# SAM9X60 device description
Architecture: ARM926EJS; Family: SAM9; Series: SAM9X
Registers are 32-bit, read-write, no defined reset value unless marked. A register's access mark holds for its fields unless they carry their own. Offsets are from the block's base; [hi:lo] are bit positions; {n}, {i} and the like mark numbered series.

## CLASSD — Audio Class D Amplifier (CLASSD)
Instances: CLASSD 0xF003C000
0x00 CLASSD_CR wo — Control Register
  [0] SWRST — Software Reset
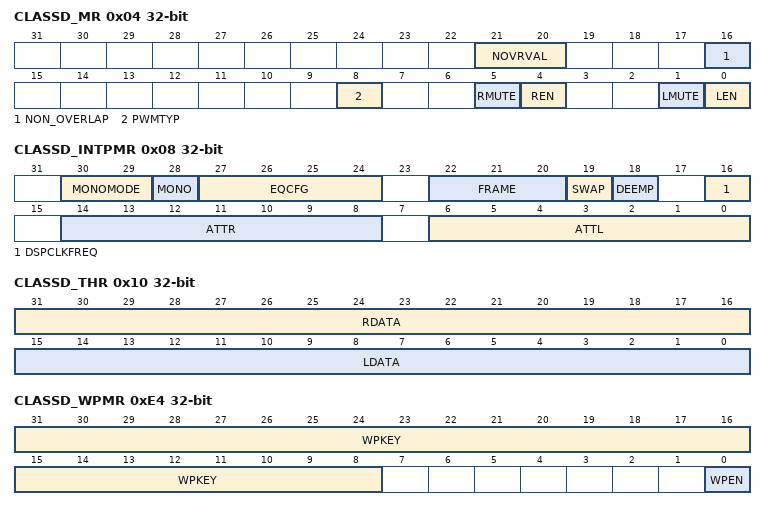
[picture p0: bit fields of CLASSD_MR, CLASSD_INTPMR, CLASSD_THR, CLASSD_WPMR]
0x04 CLASSD_MR — Mode Register
  [21:20] NOVRVAL — Non-Overlapping Value
    0=_5NS (Non-overlapping time is 5 ns); 1=_10NS (Non-overlapping time is 10 ns); 2=_15NS (Non-overlapping time is 15 ns); 3=_20NS (Non-overlapping time is 20 ns)
  [16] NON_OVERLAP — Non-Overlapping Enable
  [8] PWMTYP — PWM Modulation Type
  [5] RMUTE — Right Channel Mute
  [4] REN — Right Channel Enable
  [1] LMUTE — Left Channel Mute
  [0] LEN — Left Channel Enable
0x08 CLASSD_INTPMR — Interpolator Mode Register
  [30:29] MONOMODE — Mono Mode Selection
    0=MONOMIX ((left + right) / 2 is sent on both channels); 1=MONOSAT ((left + right) is sent to both channels. If the sum is too high, the result is saturated.); 2=MONOLEFT (THR[15:0] is sent on both left and right channels); 3=MONORIGHT (THR[31:16] is sent on both left and right channels)
  [28] MONO — Mono Signal
    0=DISABLED (The signal is sent stereo to the left and right channels.); 1=ENABLED (The same signal is sent on both left and right channels. The sent signal is defined by the MONOMODE field value.)
  [27:24] EQCFG — Equalization Selection
    0=FLAT (Flat Response); 1=BBOOST12 (Bass boost +12 dB); 2=BBOOST6 (Bass boost +6 dB); 3=BCUT12 (Bass cut -12 dB); 4=BCUT6 (Bass cut -6 dB); 5=MBOOST3 (Medium boost +3 dB); 6=MBOOST8 (Medium boost +8 dB); 7=MCUT3 (Medium cut -3 dB); 8=MCUT8 (Medium cut -8 dB); 9=TBOOST12 (Treble boost +12 dB); 10=TBOOST6 (Treble boost +6 dB); 11=TCUT12 (Treble cut -12 dB); 12=TCUT6 (Treble cut -6 dB)
  [22:20] FRAME — CLASSD Incoming Data Sampling Frequency
    0=FRAME_8K (8 kHz); 1=FRAME_16K (16 kHz); 2=FRAME_32K (32 kHz); 3=FRAME_48K (48 kHz); 4=FRAME_96K (96 kHz); 5=FRAME_22K (22.05 kHz); 6=FRAME_44K (44.1 kHz); 7=FRAME_88K (88.2 kHz)
  [19] SWAP — Swap Left and Right Channels
    0=LEFT_ON_LSB (Left channel is on CLASSD_THR[15:0], right channel is on CLASSD_THR[31:16].); 1=RIGHT_ON_LSB (Right channel is on CLASSD_THR[15:0], left channel is on CLASSD_THR[31:16].)
  [18] DEEMP — Enable De-emphasis Filter
    0=DISABLED (De-emphasis filter is disabled.); 1=ENABLED (De-emphasis filter is enabled.)
  [16] DSPCLKFREQ — DSP Clock Frequency
    0=_12M288 (DSP Clock (DSPCLK) is 12.288 MHz.); 1=_11M2896 (DSP Clock (DSPCLK) is 11.2896 MHz.)
  [14:8] ATTR — Right Channel Attenuation
  [6:0] ATTL — Left Channel Attenuation
0x0C CLASSD_INTSR ro — Interpolator Status Register
  [0] CFGERR — Configuration Error
0x10 CLASSD_THR — Transmit Holding Register
  [31:16] RDATA — Right Channel Data
  [15:0] LDATA — Left Channel Data
0x14 CLASSD_IER wo — Interrupt Enable Register
  [0] DATRDY — Data Ready
0x18 CLASSD_IDR wo — Interrupt Disable Register
  [0] DATRDY — Data Ready
0x1C CLASSD_IMR — Interrupt Mask Register
  [0] DATRDY — Data Ready
0x20 CLASSD_ISR ro — Interrupt Status Register
  [0] DATRDY — Data Ready
0xE4 CLASSD_WPMR — Write Protection Mode Register
  [31:8] WPKEY — Write Protection Key
    0x434C44=PASSWD (Writing any other value in this field aborts the write operation of the WPEN bit.Always reads as 0.)
  [0] WPEN — Write Protection Enable
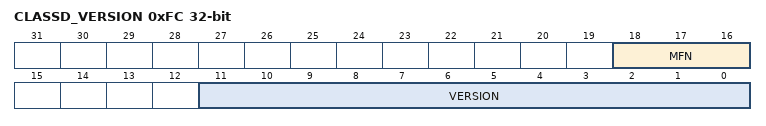
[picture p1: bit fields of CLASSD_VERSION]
0xFC CLASSD_VERSION ro — IP Version Register
  [18:16] MFN — Metal Fix Number
  [11:0] VERSION — Version of the Hardware Module

## GPBR — General Purpose Backup Registers
Instances: GPBR 0xFFFFFE60
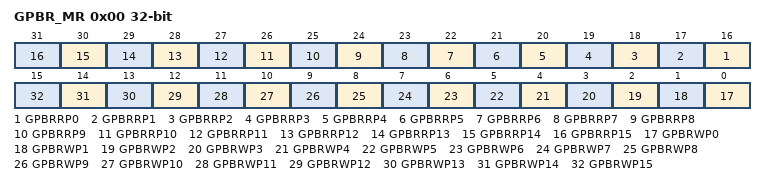
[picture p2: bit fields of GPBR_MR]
0x00 GPBR_MR — GPBR Mode Register
  [n+16] GPBRRP{n} (n=0..15) — GPBRx Read Protection
  [n] GPBRWP{n} (n=0..15) — GPBRx Write Protection
0x04 GPBR_FCLR — GPBR Full Clear Register
  [0] FCLR — Full Clear Enable
{0x8+4i} SYS_GPBR[{i}] (i=0..7) — General Purpose Backup Register
  [31:0] GPBR_VALUE — Value of SYS_GPBR x
